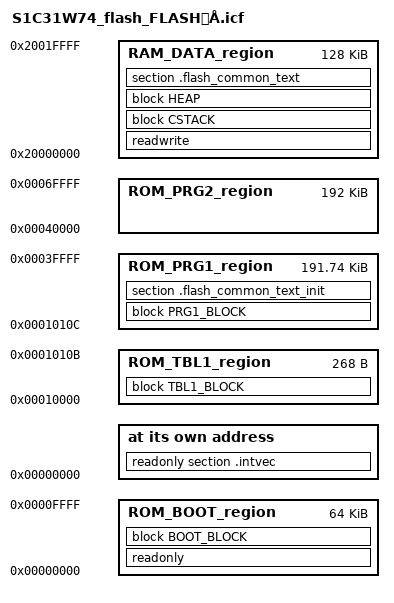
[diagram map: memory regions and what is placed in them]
/*###ICF### Section handled by ICF editor, don't touch! ****/
/*-Editor annotation file-*/
/* IcfEditorFile="$TOOLKIT_DIR$\config\ide\IcfEditor\cortex_v1_0.xml" */
/*-Specials-*/
define symbol __ICFEDIT_intvec_start__ = 0x00000000;
/*-Memory Regions-*/
define symbol __ICFEDIT_region_ROM_BOOT_start__ = 0x00000000;
define symbol __ICFEDIT_region_ROM_BOOT_end__   = 0x0000FFFF;
define symbol __ICFEDIT_region_ROM_TBL1_start__ = 0x00010000;
define symbol __ICFEDIT_region_ROM_TBL1_end__   = 0x0001010B;
define symbol __ICFEDIT_region_ROM_PRG1_start__ = 0x0001010C;
define symbol __ICFEDIT_region_ROM_PRG1_end__   = 0x0003FFFF;
define symbol __ICFEDIT_region_ROM_PRG2_start__ = 0x00040000;
define symbol __ICFEDIT_region_ROM_PRG2_end__   = 0x0006FFFF;
define symbol __ICFEDIT_region_RAM_start__      = 0x20000000;
define symbol __ICFEDIT_region_RAM_end__        = 0x2001FFFF;
/*-Sizes-*/
define symbol __ICFEDIT_size_cstack__ = 0x1000;
define symbol __ICFEDIT_size_heap__   = 0x400;
/**** End of ICF editor section. ###ICF###*/


define memory mem with size = 4G;
define region ROM_BOOT_region   = mem:[from __ICFEDIT_region_ROM_BOOT_start__   to __ICFEDIT_region_ROM_BOOT_end__];
define region ROM_TBL1_region   = mem:[from __ICFEDIT_region_ROM_TBL1_start__   to __ICFEDIT_region_ROM_TBL1_end__];
define region ROM_PRG1_region   = mem:[from __ICFEDIT_region_ROM_PRG1_start__   to __ICFEDIT_region_ROM_PRG1_end__];
define region ROM_PRG2_region   = mem:[from __ICFEDIT_region_ROM_PRG2_start__   to __ICFEDIT_region_ROM_PRG2_end__];
define region RAM_DATA_region   = mem:[from __ICFEDIT_region_RAM_start__        to __ICFEDIT_region_RAM_end__];

define block CSTACK    with alignment = 8, size = __ICFEDIT_size_cstack__   { };
define block HEAP      with alignment = 8, size = __ICFEDIT_size_heap__     { };

define block BOOT_BLOCK  { ro code object system_S1C31W74.o,
                           ro code object board.o };

define block TBL1_BLOCK  { ro code object fixed.o };
define block PRG1_BLOCK  { ro code object main.o,
                           ro code object sePeriphLibrary.a,
                           ro code object ctrl_CXD5600GF.o,
                           ro code object ctrl_GPIO.o,
                           ro code object ctrl_LSM6DSL.o,
                           ro code object ctrl_MPL3115A2.o,
                           ro code object ctrl_USB.o,
                           ro code object drv_clg.o,
                           ro code object drv_flash.o,
                           ro code object drv_gpio.o,
                           ro code object drv_i2c_0.o,
                           ro code object drv_i2c_1.o,
                           ro code object drv_rtc.o,
                           ro code object drv_t16_3.o,
                           ro code object drv_uart2_0.o,
                           ro code object drv_uart2_1.o,
                           ro code object drv_usb_main.o,
                           ro code object drv_usbd_user_cdc_acm.o,
                           ro code object drv_wdt.o,
                           ro code object gnss_gw_common.o,
                           ro code object gnss_gw_http_cmd.o,
                           ro code object man_data.o,
                           ro code object man_error.o,
                           ro code object man_gps.o,
                           ro code object man_gyro.o,
                           ro code object man_memory.o,
                           ro code object man_ope.o,
                           ro code object man_press.o,
                           ro code object man_timer.o,
                           ro code object man_usb.o,
                           ro code object mid_GPS.o,
                           ro code object usbd_cdc_acm.o,
                           ro code object usbd_core.o,
                           ro code object usbd_core_cdc.o,
                           ro code object usbd_S1C31W74.o,
                           ro code object usbd_core.o,
                           ro code object read.o, 
                           ro code object write.o,
                           ro code object FlashS1C31W74.o,
                           ro code object Driver_Flash.o };


//define block FLASH_BLOCK { ro code object read.o, 
//                           ro code object write.o,
//                           ro code object FlashS1C31W74.o,
//                           ro code object Driver_Flash.o };

initialize by copy { readwrite };

initialize manually with packing = none { section .flash_common_text};

//initialize by copy with packing = none { section __DLIB_PERTHREAD }; // Required in a multi-threaded application

do not initialize  { section .noinit };

place at address mem:__ICFEDIT_intvec_start__ { readonly section .intvec };

place in ROM_BOOT_region   { readonly, block BOOT_BLOCK };
place in ROM_TBL1_region   { block TBL1_BLOCK };
place in ROM_PRG1_region   { block PRG1_BLOCK };
place in ROM_PRG1_region   { section .flash_common_text_init};

place in RAM_DATA_region   { readwrite,
                             block CSTACK, block HEAP };
place in RAM_DATA_region   { section .flash_common_text };
